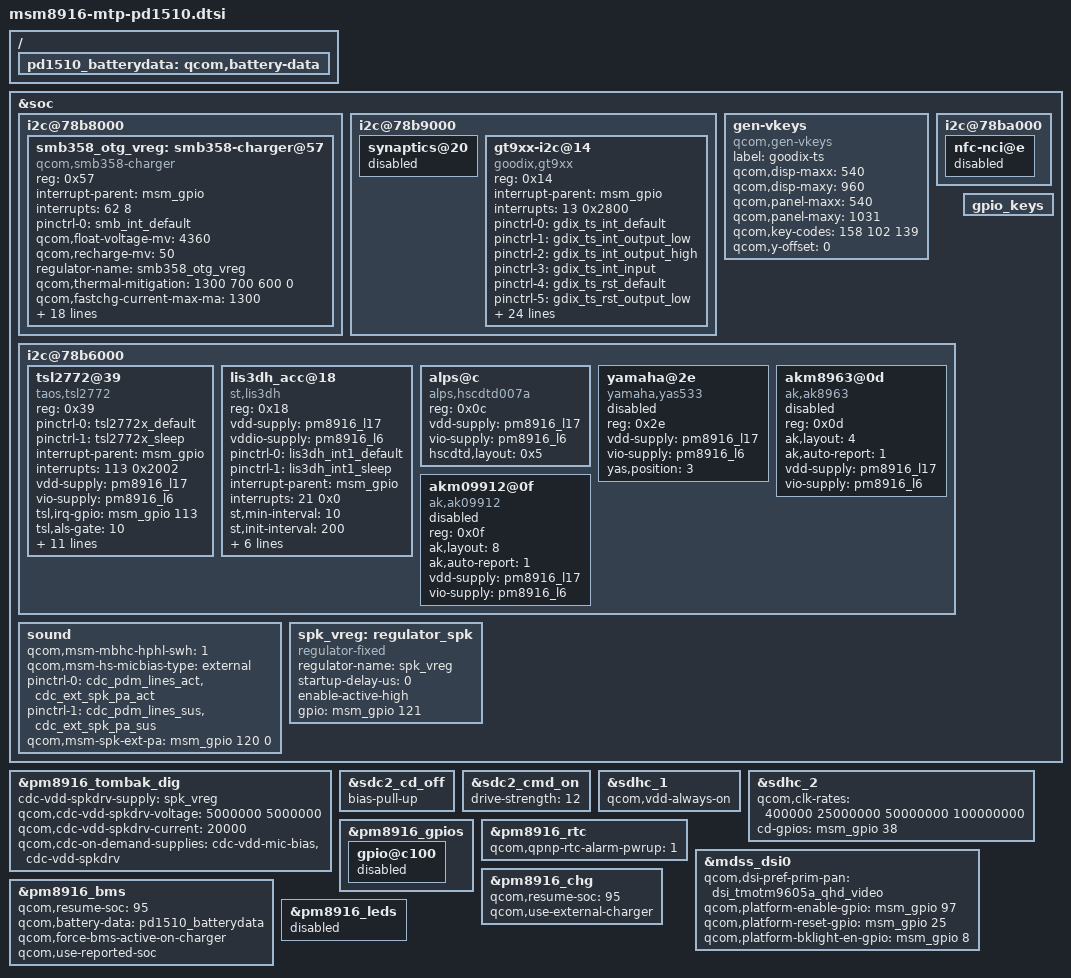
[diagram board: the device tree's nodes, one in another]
/* Copyright (c) 2018, The Linux Foundation. All rights reserved.
*  Copyright (c) 2018, Ketut P. Kumajaya.
*  Copyright (c) 2020, the_shahnawaz_sheikh (sheikhshahnawaz41299).
*
* This program is free software; you can redistribute it and/or modify
* it under the terms of the GNU General Public License version 2 and
* only version 2 as published by the Free Software Foundation.
*
* This program is distributed in the hope that it will be useful,
* but WITHOUT ANY WARRANTY; without even the implied warranty of
* MERCHANTABILITY or FITNESS FOR A PARTICULAR PURPOSE.  See the
* GNU General Public License for more details.
*/

#include "dsi-panel-tmotm9605a-qhd-video.dtsi"
#include "msm8916-camera-sensor-mtp-pd1510.dtsi"
#include "msm8916-pinctrl-pd1510.dtsi"
#include "msm8916-common-pd1510.dtsi"


&soc {

	i2c@78b8000 {
		smb358_otg_vreg: smb358-charger@57 {
			compatible = "qcom,smb358-charger";
			reg = <0x57>;
			interrupt-parent = <&msm_gpio>;
			interrupts = <62 8>;
			pinctrl-names = "default";
			pinctrl-0 = <&smb_int_default>;

			qcom,float-voltage-mv = <4360>;
			qcom,recharge-mv = <50>;
			//qcom,recharge-disabled;
			regulator-name = "smb358_otg_vreg";
			qcom,thermal-mitigation = <1300 700 600 0>;
			qcom,fastchg-current-max-ma = <1300>;

			qcom,disable-apsd;
			qcom,bms-psy-name = "bms";
			/* qcom,iterm-disabled; */
			qcom,iterm-ma = <100>;
			qcom,bms-controlled-charging;
			qcom,chg-inhibit-disabled;
			qcom,chg-vadc = <&pm8916_vadc>;
			qcom,chg-adc_tm = <&pm8916_adc_tm>;
			//qcom,vcc-i2c-supply = <&pm8916_l5>;
			qcom,irq-gpio = <&msm_gpio 62 2>;

			qcom,using-pmic-therm;
			qcom,hot-bat-decidegc = <500>;
			qcom,cold-bat-decidegc = <0>;
			qcom,bat-present-decidegc = <200>;
			/*
			 * Below properties are used for enable JEITA
			 */
			qcom,warm-bat-decidegc = <450>;
			qcom,cool-bat-decidegc = <150>;
			qcom,warm-bat-ma = <1000>;
			qcom,cool-bat-ma = <720>;
			qcom,warm-bat-mv = <4100>;
			qcom,cool-bat-mv = <4350>;
			status = "ok";
		};
	};

	

	i2c@78b9000 { /* BLSP1 QUP5 */
		synaptics@20 {
			status = "disabled";
		};

		gt9xx-i2c@14 {
			compatible = "goodix,gt9xx";
			reg = <0x14>;
			interrupt-parent = <&msm_gpio>;
			interrupts = <13 0x2800>;
			pinctrl-names = "gdix_ts_int_default",
				"gdix_ts_int_output_low",
				"gdix_ts_int_output_high",
				"gdix_ts_int_input",
				"gdix_ts_rst_default",
				"gdix_ts_rst_output_low",
				"gdix_ts_rst_output_high",
				"gdix_ts_rst_input";
			pinctrl-0 = <&gdix_ts_int_default>;
			pinctrl-1 = <&gdix_ts_int_output_low>;
			pinctrl-2 = <&gdix_ts_int_output_high>;
			pinctrl-3 = <&gdix_ts_int_input>;
			pinctrl-4 = <&gdix_ts_rst_default>;
			pinctrl-5 = <&gdix_ts_rst_output_low>;
			pinctrl-6 = <&gdix_ts_rst_output_high>;
			pinctrl-7 = <&gdix_ts_rst_input>;
			reset-gpios = <&msm_gpio 12 0x00>;
			irq-gpios = <&msm_gpio 13 0x2800>;
			irq-flags = <1>;
			vdd_ana-supply = <&pm8916_l16>;
			vcc_i2c-supply = <&pm8916_l6>;
			touchscreen-max-id = <5>;
			touchscreen-size-x = <540>;
			touchscreen-size-y = <960>;
			touchscreen-max-w = <512>;
			touchscreen-max-p = <512>;
			touchscreen-key-map = <158>, <102>, <139>; /*KEY_BACK=158，KEY_HOMEPAGE=102, KEY_MENU=139*/
			goodix,slide-wakeup = <0>;
			goodix,type-a-report = <0>;
			goodix,driver-send-cfg = <1>;
			goodix,resume-in-workqueue = <0>;
			goodix,int-sync = <1>;
			goodix,swap-x2y = <0>;
			goodix,esd-protect = <1>;
			goodix,auto-update = <0>;
			goodix,auto-update-cfg = <0>;
			goodix,power-off-sleep = <1>;
			goodix,pen-suppress-finger = <0>;
		};
	};
	
	gen-vkeys {
		compatible = "qcom,gen-vkeys";
		label = "goodix-ts";
		qcom,disp-maxx = <540>;
		qcom,disp-maxy = <960>;
		qcom,panel-maxx = <540>;
		qcom,panel-maxy = <1031>;
		qcom,key-codes = <158 102 139>;
		qcom,y-offset = <0>;
	};

	i2c@78ba000 { /* BLSP1 QUP6 */
		status = "okay";

		nfc-nci@e {
			status = "disabled";
		};
	};

	i2c@78b6000 { /* BLSP1 QUP2 */
		/delete-node/ mpu6050@68;
		/delete-node/ avago@39;
		/delete-node/ akm@c;

		tsl2772@39 {
			compatible = "taos,tsl2772";
			reg = <0x39>;
			pinctrl-names = "default","sleep";
			pinctrl-0 = <&tsl2772x_default>;
			pinctrl-1 = <&tsl2772x_sleep>;
			interrupt-parent = <&msm_gpio>;
			interrupts = <113 0x2002>;
			vdd-supply = <&pm8916_l17>;
			vio-supply = <&pm8916_l6>;
			tsl,irq-gpio = <&msm_gpio 113 0x2002>;
			tsl,als-gate = <10>;    
			tsl,als-gain = <8>;     
			tsl,control-reg = <0x21>; 
			tsl,wait-reg = <0x00>;
			tsl,ps-thdh = <950>;
			tsl,ps-thdl = <900>;
			tsl,ps-ppcount = <7>; 
			tsl,ps-thdl_offset = <90>;
			tsl,ps-thdh_offset = <180>;
			tsl,mmi-thdh-limit = <800>;
			tsl,mmi-thdl-limit = <0>;
			tsl,use-fir;
			status = "ok";
		};

		lis3dh_acc@18 {
			compatible = "st,lis3dh";
			reg = <0x18>;
			vdd-supply = <&pm8916_l17>;
			vddio-supply = <&pm8916_l6>;
			pinctrl-names = "lis3dh_default","lis3dh_sleep";
			pinctrl-0 = <&lis3dh_int1_default>;
			pinctrl-1 = <&lis3dh_int1_sleep>;
			interrupt-parent = <&msm_gpio>;
			interrupts = <21 0x0>;
			st,min-interval = <10>;
			st,init-interval = <200>;
			st,axis-map-x = <1>;
			st,axis-map-y = <0>;
			st,axis-map-z = <2>;
			st,g-range = <2>;
			/*st,negate-x;*/ /*Disabled boolean property*/
			st,negate-y; /*Enabled boolean property*/
			/*st,negate-z;*/ /*Disabled boolean property*/
			st,gpio-int1 = <&msm_gpio 21 0x2002>;
			status = "ok";
		};

		alps@c { /* Magnetic field sensor */
		     compatible = "alps,hscdtd007a";
		     reg = <0x0c>;
		     vdd-supply = <&pm8916_l17>;
		     vio-supply = <&pm8916_l6>;
		     hscdtd,layout = <0x5>;
			 status = "ok";
		};

		yamaha@2e {
			compatible = "yamaha,yas533";
			reg = <0x2e>;
			vdd-supply = <&pm8916_l17>;
			vio-supply = <&pm8916_l6>;
			yas,position = <3>;
			status = "disabled";
		};

		akm8963@0d {
			compatible = "ak,ak8963";
			reg = <0x0d>;
			ak,layout = <4>;
			ak,auto-report = <1>;
			vdd-supply = <&pm8916_l17>;
			vio-supply = <&pm8916_l6>;
			status = "disabled";
		};

		akm09912@0f {
			compatible = "ak,ak09912";
			reg = <0x0f>;
			ak,layout = <8>;
			ak,auto-report = <1>;
			vdd-supply = <&pm8916_l17>;
			vio-supply = <&pm8916_l6>;
			status = "disabled";
		};

	};

	sound {
		qcom,msm-mbhc-hphl-swh = <1>;
		qcom,msm-hs-micbias-type = "external";
		pinctrl-names = "cdc_lines_act",
				"cdc_lines_sus";
		pinctrl-0 = <&cdc_pdm_lines_act &cdc_ext_spk_pa_act>;
		pinctrl-1 = <&cdc_pdm_lines_sus &cdc_ext_spk_pa_sus>;
		/delete-property/ pinctrl-2;
		/delete-property/ pinctrl-3;
		/delete-property/ pinctrl-4;
		/delete-property/ pinctrl-5;
		/delete-property/ qcom,cdc-us-euro-gpios;
		qcom,msm-spk-ext-pa = <&msm_gpio 120 0>;
	};

	
	

	gpio_keys {
		/delete-node/ camera_focus;
		/delete-node/ camera_snapshot;
	};

	spk_vreg: regulator_spk {
		compatible = "regulator-fixed";
		regulator-name = "spk_vreg";
		startup-delay-us = <0>;
		enable-active-high;
		gpio = <&msm_gpio 121 0>;
	};
};

&pm8916_tombak_dig {
	cdc-vdd-spkdrv-supply = <&spk_vreg>;
	qcom,cdc-vdd-spkdrv-voltage = <5000000 5000000>;
	qcom,cdc-vdd-spkdrv-current = <20000>;
	qcom,cdc-on-demand-supplies = "cdc-vdd-mic-bias",
			"cdc-vdd-spkdrv";
};

&sdc2_cd_off {
	/delete-property/ bias-disable;
	bias-pull-up;
};

&sdc2_cmd_on {
	drive-strength = <12>;
};

&sdhc_1 {
	qcom,vdd-always-on;
};

&sdhc_2 {
	qcom,clk-rates = <400000 25000000 50000000 100000000>;
	cd-gpios = <&msm_gpio 38 0>;
};


&pm8916_gpios {
	gpio@c100 { /* GPIO 2 */
		status = "disabled";
	};
};

&pm8916_rtc {
	qcom,qpnp-rtc-alarm-pwrup = <1>;
};



&mdss_dsi0 {
	qcom,dsi-pref-prim-pan = <&dsi_tmotm9605a_qhd_video>;
	qcom,platform-enable-gpio = <&msm_gpio 97 0>;
	qcom,platform-reset-gpio = <&msm_gpio 25 0>;
	qcom,platform-bklight-en-gpio = <&msm_gpio 8 0>;
};

/ {
	pd1510_batterydata: qcom,battery-data {
		/delete-node/ qcom,palladium-batterydata;

		//#include "batterydata-b76-atl-4v35-2260mah.dtsi"
		//#include "batterydata-desay-samsung-2260mah.dtsi"
		//#include "batterydata-atl-ds-4v35-2300mah.dtsi"
		#include "batterydata-samsung-ds-4v35-2300mah.dtsi"
		//#include "batterydata-atl-nvt-4v35-2300mah.dtsi"
	};
};

&pm8916_chg {
	status = "ok";
	qcom,resume-soc = <95>;
	qcom,use-external-charger;
};

&pm8916_bms {
	status = "ok";
	qcom,resume-soc = <95>;
	qcom,battery-data = <&pd1510_batterydata>;
	qcom,force-bms-active-on-charger;
    qcom,use-reported-soc;
};

&pm8916_leds {
	status = "disabled";
};


